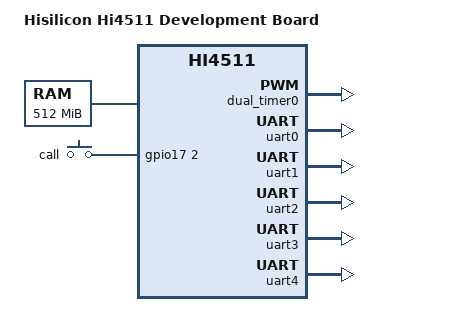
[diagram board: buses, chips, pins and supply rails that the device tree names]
/dts-v1/;
#include "hi3620.dtsi"
/ {
	model = "Hisilicon Hi4511 Development Board";
	compatible = "hisilicon,hi3620-hi4511";
	chosen {
		bootargs = "root=/dev/ram0";
		stdout-path = "serial0:115200n8";
	};
	memory@40000000 {
		device_type = "memory";
		reg = <0x40000000 0x20000000>;
	};
	amba-bus {
		dual_timer0: dual_timer@800000 {
			status = "okay";
		};
		uart0: serial@b00000 {	 
			pinctrl-names = "default", "sleep";
			pinctrl-0 = <&uart0_pmx_func &uart0_cfg_func>;
			pinctrl-1 = <&uart0_pmx_idle &uart0_cfg_idle>;
			status = "okay";
		};
		uart1: serial@b01000 {  
			pinctrl-names = "default", "sleep";
			pinctrl-0 = <&uart1_pmx_func &uart1_cfg_func>;
			pinctrl-1 = <&uart1_pmx_idle &uart1_cfg_idle>;
			status = "okay";
		};
		uart2: serial@b02000 {  
			pinctrl-names = "default", "sleep";
			pinctrl-0 = <&uart2_pmx_func &uart2_cfg_func>;
			pinctrl-1 = <&uart2_pmx_idle &uart2_cfg_idle>;
			status = "okay";
		};
		uart3: serial@b03000 {
			pinctrl-names = "default", "sleep";
			pinctrl-0 = <&uart3_pmx_func &uart3_cfg_func>;
			pinctrl-1 = <&uart3_pmx_idle &uart3_cfg_idle>;
			status = "okay";
		};
		uart4: serial@b04000 {
			pinctrl-names = "default", "sleep";
			pinctrl-0 = <&uart4_pmx_func &uart4_cfg_func>;
			pinctrl-1 = <&uart4_pmx_idle &uart4_cfg_func>;
			status = "okay";
		};
		pmx0: pinmux@803000 {
			pinctrl-names = "default";
			pinctrl-0 = <&board_pmx_pins>;
			board_pmx_pins: board-pins {
				pinctrl-single,pins = <
					0x008 0x0	 
					0x100 0x0	 
				>;
			};
			uart0_pmx_func: uart0-pins {
				pinctrl-single,pins = <
					0x0f0 0x0
					0x0f4 0x0	 
				>;
			};
			uart0_pmx_idle: uart0-idle-pins {
				pinctrl-single,pins = <
					0x0f4 0x1	 
				>;
			};
			uart1_pmx_func: uart1-pins {
				pinctrl-single,pins = <
					0x0f8 0x0	 
					0x0fc 0x0	 
				>;
			};
			uart1_pmx_idle: uart1-idle-pins {
				pinctrl-single,pins = <
					0x0f8 0x1	 
					0x0fc 0x1	 
				>;
			};
			uart2_pmx_func: uart2-pins {
				pinctrl-single,pins = <
					0x104 0x2	 
					0x108 0x2	 
				>;
			};
			uart2_pmx_idle: uart2-idle-pins {
				pinctrl-single,pins = <
					0x104 0x1	 
					0x108 0x1	 
				>;
			};
			uart3_pmx_func: uart3-pins {
				pinctrl-single,pins = <
					0x160 0x2	 
					0x164 0x2	 
				>;
			};
			uart3_pmx_idle: uart3-idle-pins {
				pinctrl-single,pins = <
					0x160 0x1	 
					0x164 0x1	 
				>;
			};
			uart4_pmx_func: uart4-pins {
				pinctrl-single,pins = <
					0x168 0x0	 
					0x16c 0x0	 
					0x170 0x0	 
				>;
			};
			uart4_pmx_idle: uart4-idle-pins {
				pinctrl-single,pins = <
					0x168 0x1	 
					0x16c 0x1	 
					0x170 0x1	 
				>;
			};
			i2c0_pmx_func: i2c0-pins {
				pinctrl-single,pins = <
					0x0b4 0x0	 
				>;
			};
			i2c0_pmx_idle: i2c0-idle-pins {
				pinctrl-single,pins = <
					0x0b4 0x1	 
				>;
			};
			i2c1_pmx_func: i2c1-pins {
				pinctrl-single,pins = <
					0x0b8 0x0	 
				>;
			};
			i2c1_pmx_idle: i2c1-idle-pins {
				pinctrl-single,pins = <
					0x0b8 0x1	 
				>;
			};
			i2c2_pmx_func: i2c2-pins {
				pinctrl-single,pins = <
					0x068 0x0	 
					0x06c 0x0	 
				>;
			};
			i2c2_pmx_idle: i2c2-idle-pins {
				pinctrl-single,pins = <
					0x068 0x1	 
					0x06c 0x1	 
				>;
			};
			i2c3_pmx_func: i2c3-pins {
				pinctrl-single,pins = <
					0x050 0x2	 
					0x054 0x2	 
				>;
			};
			i2c3_pmx_idle: i2c3-idle-pins {
				pinctrl-single,pins = <
					0x050 0x1	 
					0x054 0x1	 
				>;
			};
			spi0_pmx_func: spi0-pins {
				pinctrl-single,pins = <
					0x0d4 0x0	 
					0x0d8 0x0	 
					0x0dc 0x0	 
					0x0e0 0x0	 
					0x0e4 0x0	 
				>;
			};
			spi0_pmx_idle: spi0-idle-pins {
				pinctrl-single,pins = <
					0x0d4 0x1	 
					0x0d8 0x1	 
					0x0dc 0x1	 
					0x0e0 0x1	 
					0x0e4 0x1	 
				>;
			};
			spi1_pmx_func: spi1-pins {
				pinctrl-single,pins = <
					0x184 0x0	 
					0x0e8 0x0	 
					0x0ec 0x0	 
				>;
			};
			spi1_pmx_idle: spi1-idle-pins {
				pinctrl-single,pins = <
					0x184 0x1	 
					0x0e8 0x1	 
					0x0ec 0x1	 
				>;
			};
			kpc_pmx_func: kpc-pins {
				pinctrl-single,pins = <
					0x12c 0x0	 
					0x130 0x0	 
					0x134 0x0	 
					0x10c 0x0	 
					0x110 0x0	 
					0x114 0x0	 
				>;
			};
			kpc_pmx_idle: kpc-idle-pins {
				pinctrl-single,pins = <
					0x12c 0x1	 
					0x130 0x1	 
					0x134 0x1	 
					0x10c 0x1	 
					0x110 0x1	 
					0x114 0x1	 
				>;
			};
			gpio_key_func: gpio-key-pins {
				pinctrl-single,pins = <
					0x10c 0x1	 
					0x130 0x1	 
				>;
			};
			emmc_pmx_func: emmc-pins {
				pinctrl-single,pins = <
					0x030 0x2	 
					0x018 0x0	 
					0x024 0x0	 
					0x028 0x0	 
					0x02c 0x2	 
				>;
			};
			emmc_pmx_idle: emmc-idle-pins {
				pinctrl-single,pins = <
					0x030 0x0	 
					0x018 0x1	 
					0x024 0x1	 
					0x028 0x1	 
					0x02c 0x1	 
				>;
			};
			sd_pmx_func: sd-pins {
				pinctrl-single,pins = <
					0x0bc 0x0	 
					0x0c0 0x0	 
				>;
			};
			sd_pmx_idle: sd-idle-pins {
				pinctrl-single,pins = <
					0x0bc 0x1	 
					0x0c0 0x1	 
				>;
			};
			nand_pmx_func: nand-pins {
				pinctrl-single,pins = <
					0x00c 0x0	 
					0x010 0x0	 
					0x014 0x0	 
					0x018 0x0	 
					0x01c 0x0	 
					0x020 0x0	 
					0x024 0x0	 
					0x028 0x0	 
					0x02c 0x0	 
				>;
			};
			nand_pmx_idle: nand-idle-pins {
				pinctrl-single,pins = <
					0x00c 0x1	 
					0x010 0x1	 
					0x014 0x1	 
					0x018 0x1	 
					0x01c 0x1	 
					0x020 0x1	 
					0x024 0x1	 
					0x028 0x1	 
					0x02c 0x1	 
				>;
			};
			sdio_pmx_func: sdio-pins {
				pinctrl-single,pins = <
					0x0c4 0x0	 
				>;
			};
			sdio_pmx_idle: sdio-idle-pins {
				pinctrl-single,pins = <
					0x0c4 0x1	 
				>;
			};
			audio_out_pmx_func: audio-out-pins {
				pinctrl-single,pins = <
					0x0f0 0x1	 
				>;
			};
		};
		pmx1: pinmux@803800 {
			pinctrl-names = "default";
			pinctrl-0 = <	&board_pu_pins &board_pd_pins &board_pd_ps_pins
					&board_np_pins &board_ps_pins &kpc_cfg_func
					&audio_out_cfg_func>;
			board_pu_pins: board-pu-pins {
				pinctrl-single,pins = <
					0x014 0		 
					0x018 0		 
					0x01c 0		 
					0x020 0		 
				>;
				pinctrl-single,bias-pulldown = <0 2 0 2>;
				pinctrl-single,bias-pullup = <1 1 0 1>;
			};
			board_pd_pins: board-pd-pins {
				pinctrl-single,pins = <
					0x038 0		 
					0x150 0		 
					0x154 0		 
				>;
				pinctrl-single,bias-pulldown = <2 2 0 2>;
				pinctrl-single,bias-pullup = <0 1 0 1>;
			};
			board_pd_ps_pins: board-pd-ps-pins {
				pinctrl-single,pins = <
					0x2d8 0		 
					0x004 0		 
				>;
				pinctrl-single,bias-pulldown = <2 2 0 2>;
				pinctrl-single,bias-pullup = <0 1 0 1>;
				pinctrl-single,drive-strength = <0x30 0xf0>;
			};
			board_np_pins: board-np-pins {
				pinctrl-single,pins = <
					0x24c 0		 
				>;
				pinctrl-single,bias-pulldown = <0 2 0 2>;
				pinctrl-single,bias-pullup = <0 1 0 1>;
			};
			board_ps_pins: board-ps-pins {
				pinctrl-single,pins = <
					0x000 0		 
					0x008 0		 
				>;
				pinctrl-single,drive-strength = <0x30 0xf0>;
			};
			uart0_cfg_func: uart0-cfg-pins {
				pinctrl-single,pins = <
					0x208 0		 
					0x20c 0		 
				>;
				pinctrl-single,bias-pulldown = <0 2 0 2>;
				pinctrl-single,bias-pullup = <0 1 0 1>;
			};
			uart0_cfg_idle: uart0-cfg-idle-pins {
				pinctrl-single,pins = <
					0x208 0		 
					0x20c 0		 
				>;
				pinctrl-single,bias-pulldown = <2 2 0 2>;
				pinctrl-single,bias-pullup = <0 1 0 1>;
			};
			uart1_cfg_func: uart1-cfg-pins {
				pinctrl-single,pins = <
					0x210 0		 
					0x214 0		 
					0x218 0		 
					0x21c 0		 
				>;
				pinctrl-single,bias-pulldown = <0 2 0 2>;
				pinctrl-single,bias-pullup = <0 1 0 1>;
			};
			uart1_cfg_idle: uart1-cfg-idle-pins {
				pinctrl-single,pins = <
					0x210 0		 
					0x214 0		 
					0x218 0		 
					0x21c 0		 
				>;
				pinctrl-single,bias-pulldown = <2 2 0 2>;
				pinctrl-single,bias-pullup = <0 1 0 1>;
			};
			uart2_cfg_func: uart2-cfg-pins {
				pinctrl-single,pins = <
					0x220 0		 
					0x224 0		 
					0x228 0		 
					0x22c 0		 
				>;
				pinctrl-single,bias-pulldown = <0 2 0 2>;
				pinctrl-single,bias-pullup = <0 1 0 1>;
			};
			uart2_cfg_idle: uart2-cfg-idle-pins {
				pinctrl-single,pins = <
					0x220 0		 
					0x224 0		 
					0x228 0		 
					0x22c 0		 
				>;
				pinctrl-single,bias-pulldown = <2 2 0 2>;
				pinctrl-single,bias-pullup = <0 1 0 1>;
			};
			uart3_cfg_func: uart3-cfg-pins {
				pinctrl-single,pins = <
					0x294 0		 
					0x298 0		 
					0x29c 0		 
					0x2a0 0		 
				>;
				pinctrl-single,bias-pulldown = <0 2 0 2>;
				pinctrl-single,bias-pullup = <0 1 0 1>;
			};
			uart3_cfg_idle: uart3-cfg-idle-pins {
				pinctrl-single,pins = <
					0x294 0		 
					0x298 0		 
					0x29c 0		 
					0x2a0 0		 
				>;
				pinctrl-single,bias-pulldown = <2 2 0 2>;
				pinctrl-single,bias-pullup = <0 1 0 1>;
			};
			uart4_cfg_func: uart4-cfg-pins {
				pinctrl-single,pins = <
					0x2a4 0		 
					0x2a8 0		 
					0x2ac 0		 
					0x2b0 0		 
				>;
				pinctrl-single,bias-pulldown = <0 2 0 2>;
				pinctrl-single,bias-pullup = <0 1 0 1>;
			};
			i2c0_cfg_func: i2c0-cfg-pins {
				pinctrl-single,pins = <
					0x17c 0		 
					0x180 0		 
				>;
				pinctrl-single,bias-pulldown = <0 2 0 2>;
				pinctrl-single,bias-pullup = <0 1 0 1>;
				pinctrl-single,drive-strength = <0x30 0xf0>;
			};
			i2c1_cfg_func: i2c1-cfg-pins {
				pinctrl-single,pins = <
					0x184 0		 
					0x188 0		 
				>;
				pinctrl-single,bias-pulldown = <0 2 0 2>;
				pinctrl-single,bias-pullup = <0 1 0 1>;
				pinctrl-single,drive-strength = <0x30 0xf0>;
			};
			i2c2_cfg_func: i2c2-cfg-pins {
				pinctrl-single,pins = <
					0x118 0		 
					0x11c 0		 
				>;
				pinctrl-single,bias-pulldown = <0 2 0 2>;
				pinctrl-single,bias-pullup = <0 1 0 1>;
				pinctrl-single,drive-strength = <0x30 0xf0>;
			};
			i2c3_cfg_func: i2c3-cfg-pins {
				pinctrl-single,pins = <
					0x100 0		 
					0x104 0		 
				>;
				pinctrl-single,bias-pulldown = <0 2 0 2>;
				pinctrl-single,bias-pullup = <0 1 0 1>;
				pinctrl-single,drive-strength = <0x30 0xf0>;
			};
			spi0_cfg_func1: spi0-cfg-func1-pins {
				pinctrl-single,pins = <
					0x1d4 0		 
					0x1d8 0		 
					0x1dc 0		 
				>;
				pinctrl-single,bias-pulldown = <2 2 0 2>;
				pinctrl-single,bias-pullup = <0 1 0 1>;
				pinctrl-single,drive-strength = <0x30 0xf0>;
			};
			spi0_cfg_func2: spi0-cfg-func2-pins {
				pinctrl-single,pins = <
					0x1e0 0		 
					0x1e4 0		 
					0x1e8 0		 
					0x1ec 0		 
				>;
				pinctrl-single,bias-pulldown = <0 2 0 2>;
				pinctrl-single,bias-pullup = <1 1 0 1>;
				pinctrl-single,drive-strength = <0x30 0xf0>;
			};
			spi1_cfg_func1: spi1-cfg-func1-pins {
				pinctrl-single,pins = <
					0x1f0 0		 
					0x1f4 0		 
					0x1f8 0		 
				>;
				pinctrl-single,bias-pulldown = <2 2 0 2>;
				pinctrl-single,bias-pullup = <0 1 0 1>;
				pinctrl-single,drive-strength = <0x30 0xf0>;
			};
			spi1_cfg_func2: spi1-cfg-func2-pins {
				pinctrl-single,pins = <
					0x1fc 0		 
				>;
				pinctrl-single,bias-pulldown = <0 2 0 2>;
				pinctrl-single,bias-pullup = <1 1 0 1>;
				pinctrl-single,drive-strength = <0x30 0xf0>;
			};
			kpc_cfg_func: kpc-cfg-pins {
				pinctrl-single,pins = <
					0x250 0		 
					0x254 0		 
					0x258 0		 
					0x230 0		 
					0x234 0		 
					0x238 0		 
				>;
				pinctrl-single,bias-pulldown = <2 2 0 2>;
				pinctrl-single,bias-pullup = <0 1 0 1>;
			};
			emmc_cfg_func: emmc-cfg-pins {
				pinctrl-single,pins = <
					0x0ac 0		 
					0x0b0 0		 
					0x058 0		 
					0x064 0		 
					0x068 0		 
					0x08c 0		 
					0x090 0		 
					0x094 0		 
					0x098 0		 
					0x09c 0		 
					0x0a0 0		 
					0x0a4 0		 
					0x0a8 0		 
				>;
				pinctrl-single,bias-pulldown = <0 2 0 2>;
				pinctrl-single,bias-pullup = <1 1 0 1>;
				pinctrl-single,drive-strength = <0x30 0xf0>;
			};
			sd_cfg_func1: sd-cfg-func1-pins {
				pinctrl-single,pins = <
					0x18c 0		 
					0x190 0		 
				>;
				pinctrl-single,bias-pulldown = <2 2 0 2>;
				pinctrl-single,bias-pullup = <0 1 0 1>;
				pinctrl-single,drive-strength = <0x30 0xf0>;
			};
			sd_cfg_func2: sd-cfg-func2-pins {
				pinctrl-single,pins = <
					0x194 0		 
					0x198 0		 
					0x19c 0		 
					0x1a0 0		 
				>;
				pinctrl-single,bias-pulldown = <2 2 0 2>;
				pinctrl-single,bias-pullup = <0 1 0 1>;
				pinctrl-single,drive-strength = <0x70 0xf0>;
			};
			nand_cfg_func1: nand-cfg-func1-pins {
				pinctrl-single,pins = <
					0x03c 0		 
					0x040 0		 
					0x06c 0		 
					0x070 0		 
					0x074 0		 
					0x078 0		 
					0x07c 0		 
					0x080 0		 
					0x084 0		 
					0x088 0		 
					0x08c 0		 
					0x090 0		 
					0x094 0		 
					0x098 0		 
					0x09c 0		 
					0x0a0 0		 
					0x0a4 0		 
					0x0a8 0		 
				>;
				pinctrl-single,bias-pulldown = <2 2 0 2>;
				pinctrl-single,bias-pullup = <0 1 0 1>;
				pinctrl-single,drive-strength = <0x30 0xf0>;
			};
			nand_cfg_func2: nand-cfg-func2-pins {
				pinctrl-single,pins = <
					0x044 0		 
					0x048 0		 
					0x04c 0		 
					0x050 0		 
					0x054 0		 
					0x058 0		 
					0x05c 0		 
					0x060 0		 
					0x064 0		 
					0x068 0		 
				>;
				pinctrl-single,bias-pulldown = <0 2 0 2>;
				pinctrl-single,bias-pullup = <1 1 0 1>;
				pinctrl-single,drive-strength = <0x30 0xf0>;
			};
			sdio_cfg_func: sdio-cfg-pins {
				pinctrl-single,pins = <
					0x1a4 0		 
					0x1a8 0		 
					0x1ac 0		 
					0x1b0 0		 
					0x1b4 0		 
					0x1b8 0		 
				>;
				pinctrl-single,bias-pulldown = <2 2 0 2>;
				pinctrl-single,bias-pullup = <0 1 0 1>;
				pinctrl-single,drive-strength = <0x30 0xf0>;
			};
			audio_out_cfg_func: audio-out-cfg-pins {
				pinctrl-single,pins = <
					0x200 0		 
					0x204 0		 
				>;
				pinctrl-single,bias-pulldown = <2 2 0 2>;
				pinctrl-single,bias-pullup = <0 1 0 1>;
			};
		};
	};
	gpio-keys {
		compatible = "gpio-keys";
		call {
			label = "call";
			gpios = <&gpio17 2 0>;
			linux,code = <169>;	 
		};
	};
};
